# desdma register map
Vendor: Texas Instruments
Peripheral module from a debugger description file (folder MSP432E4).
Registers are 32-bit, read-only, no defined reset value unless marked. A register's access mark holds for its fields unless they carry their own. Offsets are as the file gives them; lines under a group give offsets from that group; [hi:lo] are bit positions; {n}, {i} and the like mark numbered series; 'fields as' and 'values as' point back to an identical list; <NAME> marks a mode.

## DES_DMA — DES DMA register offsets
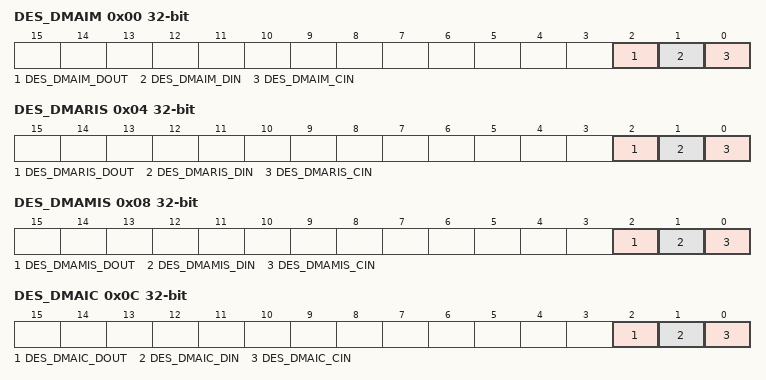
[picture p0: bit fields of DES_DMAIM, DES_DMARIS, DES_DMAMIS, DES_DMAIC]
0x00 DES_DMAIM rw — DES DMA Interrupt Mask
  [2] DES_DMAIM_DOUT — Data Out DMA Done Interrupt Mask
  [1] DES_DMAIM_DIN — Data In DMA Done Interrupt Mask
  [0] DES_DMAIM_CIN — Context In DMA Done Interrupt Mask
0x04 DES_DMARIS — DES DMA Raw Interrupt Status
  [2] DES_DMARIS_DOUT — Data Out DMA Done Raw Interrupt Status
  [1] DES_DMARIS_DIN — Data In DMA Done Raw Interrupt Status
  [0] DES_DMARIS_CIN — Context In DMA Done Raw Interrupt Status
0x08 DES_DMAMIS — DES DMA Masked Interrupt Status
  [2] DES_DMAMIS_DOUT — Data Out DMA Done Masked Interrupt Status
  [1] DES_DMAMIS_DIN — Data In DMA Done Masked Interrupt Status
  [0] DES_DMAMIS_CIN — Context In DMA Done Raw Interrupt Status
0x0C DES_DMAIC wo — DES DMA Interrupt Clear
  [2] DES_DMAIC_DOUT — Data Out DMA Done Interrupt Clear
  [1] DES_DMAIC_DIN — Data In DMA Done Interrupt Clear
  [0] DES_DMAIC_CIN — Context In DMA Done Raw Interrupt Status
